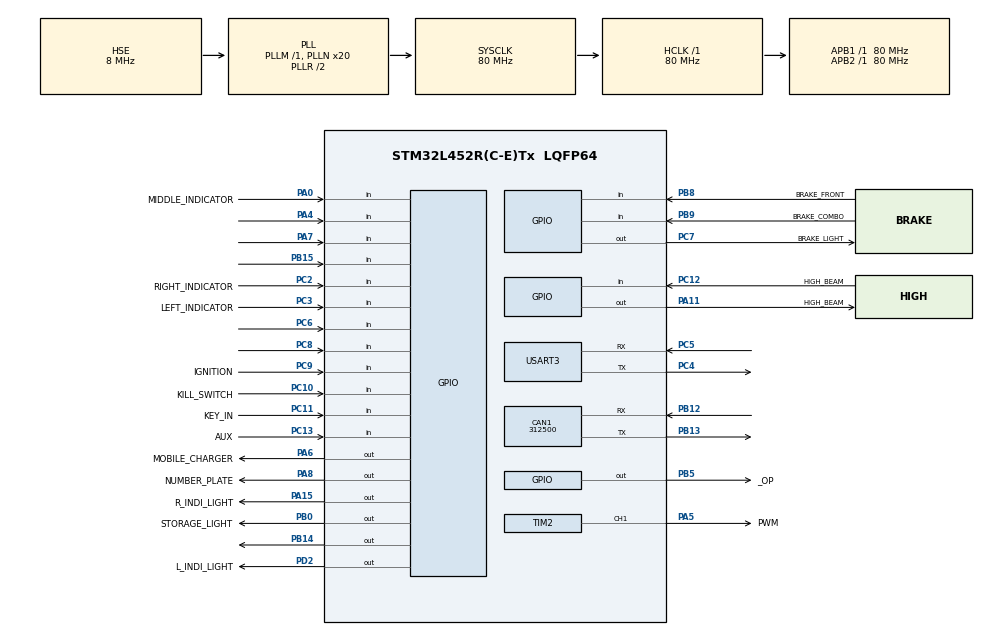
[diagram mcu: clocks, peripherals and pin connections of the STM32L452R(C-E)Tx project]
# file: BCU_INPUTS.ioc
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Mcu.Family=STM32L4
NVIC.CAN1_RX1_IRQn=true\:0\:0\:false\:false\:true\:true\:true
RCC.CortexFreq_Value=80000000
PC10.GPIO_PuPd=GPIO_NOPULL
PH0-OSC_IN\ (PH0).Signal=RCC_OSC_IN
PC12.Signal=GPIO_Input
PC10.Signal=GPIO_Input
PA0.GPIO_Label=MIDDLE_INDICATOR
PA6.GPIO_Label=MOBILE_CHARGER
PB0.GPIO_Label=STORAGE_LIGHT
PA15\ (JTDI).Signal=GPIO_Output
PC5.Mode=Asynchronous
PC13.GPIO_Label=AUX
PB13.Signal=CAN1_TX
PB15.Signal=GPIO_Input
RCC.SYSCLKSource=RCC_SYSCLKSOURCE_PLLCLK
ProjectManager.StackSize=0x400
USART3.VirtualMode-Asynchronous=VM_ASYNC
PC11.GPIO_PuPd=GPIO_NOPULL
PA14\ (JTCK/SWCLK).Signal=SYS_JTCK-SWCLK
NVIC.CAN1_TX_IRQn=true\:0\:0\:false\:false\:true\:true\:true
RCC.HCLKFreq_Value=80000000
RCC.APB2TimFreq_Value=80000000
TIM3.Period=10000
PC7.Signal=GPIO_Output
PC3.Signal=GPIO_Input
NVIC.CAN1_SCE_IRQn=true\:0\:0\:false\:false\:true\:true\:true
RCC.AHBFreq_Value=80000000
PH1-OSC_OUT\ (PH1).Mode=HSE-External-Oscillator
RCC.HSE_VALUE=8000000
PA4.GPIO_PuPd=GPIO_NOPULL
TIM3.Prescaler=4
PC11.GPIO_Label=KEY_IN
PC13.GPIO_PuPd=GPIO_NOPULL
PA8.Signal=GPIO_Output
PA14\ (JTCK/SWCLK).Mode=Serial_Wire
TIM2.Channel-PWM\ Generation1\ CH1=TIM_CHANNEL_1
PA0.Signal=GPIO_Input
Mcu.Package=LQFP64
PB9.Signal=GPIO_Input
TIM2.Prescaler=1600
PA6.Signal=GPIO_Output
PB12.Mode=CAN_Activate
PB15.GPIO_PuPd=GPIO_NOPULL
PA0.GPIO_PuPd=GPIO_NOPULL
PB9.GPIO_PuPd=GPIO_NOPULL
PC6.GPIO_PuPd=GPIO_NOPULL
PB5.GPIO_Label=_OP
RCC.APB1TimFreq_Value=80000000
PC5.Signal=USART3_RX
PB13.Mode=CAN_Activate
PC12.GPIO_PuPd=GPIO_NOPULL
CAN1.CalculateTimeBit=3200.00
PH0-OSC_IN\ (PH0).Mode=HSE-External-Oscillator
PC2.GPIO_Label=RIGHT_INDICATOR
VP_TIM3_VS_ClockSourceINT.Mode=Internal
PC4.Mode=Asynchronous
RCC.HSI48_VALUE=48000000
CAN1.CalculateTimeQuantum=200.0
RCC.MSI_VALUE=4000000
RCC.PLLSourceVirtual=RCC_PLLSOURCE_HSE
SH.S_TIM2_CH1.0=TIM2_CH1,PWM Generation1 CH1
PA13\ (JTMS/SWDIO).Mode=Serial_Wire
PB9.GPIO_Label=BRAKE_COMBO
PC10.GPIO_Label=KILL_SWITCH
PC9.GPIO_Label=IGNITION
TIM3.AutoReloadPreload=TIM_AUTORELOAD_PRELOAD_ENABLE
PC11.Signal=GPIO_Input
PC13.Signal=GPIO_Input
CAN1.CalculateBaudRate=312500
PC8.Signal=GPIO_Input
PB8.GPIO_PuPd=GPIO_NOPULL
PC2.Signal=GPIO_Input
PC4.Signal=USART3_TX
PC6.Signal=GPIO_Input
PA11.GPIO_Label=HIGH_BEAM
PH1-OSC_OUT\ (PH1).Signal=RCC_OSC_OUT
PB8.GPIO_Label=BRAKE_FRONT
PA8.GPIO_Label=NUMBER_PLATE
CAN1.BS2=CAN_BS2_2TQ
CAN1.BS1=CAN_BS1_13TQ
ProjectManager.TargetToolchain=STM32CubeIDE
RCC.USBFreq_Value=32000000
RCC.LSE_VALUE=32768
PA7.GPIO_PuPd=GPIO_NOPULL
PB14.Signal=GPIO_Output
PA5.Signal=S_TIM2_CH1
board=custom
RCC.VCOOutputFreq_Value=160000000
NVIC.TIM3_IRQn=true\:0\:0\:false\:false\:true\:true\:true
RCC.APB2Freq_Value=80000000
VP_TIM2_VS_ClockSourceINT.Mode=Internal
RCC.ADCFreq_Value=32000000
PC9.GPIO_PuPd=GPIO_NOPULL
PC2.GPIO_PuPd=GPIO_NOPULL
TIM2.Period=1000
PA15\ (JTDI).GPIO_Label=R_INDI_LIGHT
Mcu.Name=STM32L452R(C-E)Tx
PC7.GPIO_Label=BRAKE_LIGHT
PC8.GPIO_PuPd=GPIO_NOPULL
PA4.Signal=GPIO_Input
RCC.SYSCLKFreq_VALUE=80000000
PB5.Signal=GPIO_Output
PA5.GPIO_Label=PWM
PC12.GPIO_Label=HIGH_BEAM
PA11.Signal=GPIO_Output
ProjectManager.HeapSize=0x200
RCC.HSI_VALUE=16000000
NVIC.PriorityGroup=NVIC_PRIORITYGROUP_4
RCC.PLLN=20
PB8.Signal=GPIO_Input
TIM2.AutoReloadPreload=TIM_AUTORELOAD_PRELOAD_ENABLE
PC3.GPIO_Label=LEFT_INDICATOR
PC9.Signal=GPIO_Input
PD2.Signal=GPIO_Output
RCC.APB1Freq_Value=80000000
PB0.Signal=GPIO_Output
PB12.Signal=CAN1_RX
PD2.GPIO_Label=L_INDI_LIGHT
NVIC.CAN1_RX0_IRQn=true\:0\:0\:false\:false\:true\:true\:true
PA13\ (JTMS/SWDIO).Signal=SYS_JTMS-SWDIO
PC3.GPIO_PuPd=GPIO_NOPULL
PA7.Signal=GPIO_Input

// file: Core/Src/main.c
/* USER CODE BEGIN Header */
/**
  ******************************************************************************
  * @file           : main.c
  * @brief          : Main program body
  ******************************************************************************
  * @attention
  *
  * <h2><center>&copy; Copyright (c) 2021 STMicroelectronics.
  * All rights reserved.</center></h2>
  *
  * This software component is licensed by ST under BSD 3-Clause license,
  * the "License"; You may not use this file except in compliance with the
  * License. You may obtain a copy of the License at:
  *                        opensource.org/licenses/BSD-3-Clause
  *
  ******************************************************************************
  */
/* USER CODE END Header */
#include "main.h"

CAN_HandleTypeDef hcan1;

TIM_HandleTypeDef htim2;
TIM_HandleTypeDef htim3;

UART_HandleTypeDef huart3;

void SystemClock_Config(void);
static void MX_GPIO_Init(void);
static void MX_CAN1_Init(void);
static void MX_TIM2_Init(void);
static void MX_USART3_UART_Init(void);
static void MX_TIM3_Init(void);

int main(void)
{

  /* MCU Configuration--------------------------------------------------------*/

  /* Reset of all peripherals, Initializes the Flash interface and the Systick. */
  HAL_Init();

  /* Configure the system clock */
  SystemClock_Config();

  /* Initialize all configured peripherals */
  MX_GPIO_Init();
  MX_CAN1_Init();
  MX_TIM2_Init();
  MX_USART3_UART_Init();
  MX_TIM3_Init();
  /* USER CODE BEGIN 2 */
  HAL_TIM_PWM_Start(&htim2, TIM_CHANNEL_1);

  /* USER CODE END 2 */

  /* Infinite loop */
  /* USER CODE BEGIN WHILE */
  while (1)
  {
	  	  htim2.Instance->CCR1 = 50;  // duty cycle is 1ms  0deg
		  HAL_Delay(2000);
		  htim2.Instance->CCR1 = 100;  // duty cycle is 2 ms 180deg
		  HAL_Delay(2000);
		  htim2.Instance->CCR1 = 75;  // duty cycle is 1.5 ms  90deg
		  HAL_Delay(2000);
		  htim2.Instance->CCR1 = 50;  // duty cycle is  1ms  0deg
		  HAL_Delay(2000);

    /* USER CODE END WHILE */

  }
}

void SystemClock_Config(void)
{
  RCC_OscInitTypeDef RCC_OscInitStruct = {0};
  RCC_ClkInitTypeDef RCC_ClkInitStruct = {0};
  RCC_PeriphCLKInitTypeDef PeriphClkInit = {0};

  /** Initializes the RCC Oscillators according to the specified parameters
  * in the RCC_OscInitTypeDef structure.
  */
  RCC_OscInitStruct.OscillatorType = RCC_OSCILLATORTYPE_HSE;
  RCC_OscInitStruct.HSEState = RCC_HSE_ON;
  RCC_OscInitStruct.PLL.PLLState = RCC_PLL_ON;
  RCC_OscInitStruct.PLL.PLLSource = RCC_PLLSOURCE_HSE;
  RCC_OscInitStruct.PLL.PLLM = 1;
  RCC_OscInitStruct.PLL.PLLN = 20;
  RCC_OscInitStruct.PLL.PLLP = RCC_PLLP_DIV7;
  RCC_OscInitStruct.PLL.PLLQ = RCC_PLLQ_DIV2;
  RCC_OscInitStruct.PLL.PLLR = RCC_PLLR_DIV2;
  if (HAL_RCC_OscConfig(&RCC_OscInitStruct) != HAL_OK)
  {
    Error_Handler();
  }
  /** Initializes the CPU, AHB and APB buses clocks
  */
  RCC_ClkInitStruct.ClockType = RCC_CLOCKTYPE_HCLK|RCC_CLOCKTYPE_SYSCLK
                              |RCC_CLOCKTYPE_PCLK1|RCC_CLOCKTYPE_PCLK2;
  RCC_ClkInitStruct.SYSCLKSource = RCC_SYSCLKSOURCE_PLLCLK;
  RCC_ClkInitStruct.AHBCLKDivider = RCC_SYSCLK_DIV1;
  RCC_ClkInitStruct.APB1CLKDivider = RCC_HCLK_DIV1;
  RCC_ClkInitStruct.APB2CLKDivider = RCC_HCLK_DIV1;

  if (HAL_RCC_ClockConfig(&RCC_ClkInitStruct, FLASH_LATENCY_4) != HAL_OK)
  {
    Error_Handler();
  }
  PeriphClkInit.PeriphClockSelection = RCC_PERIPHCLK_USART3;
  PeriphClkInit.Usart3ClockSelection = RCC_USART3CLKSOURCE_PCLK1;
  if (HAL_RCCEx_PeriphCLKConfig(&PeriphClkInit) != HAL_OK)
  {
    Error_Handler();
  }
  /** Configure the main internal regulator output voltage
  */
  if (HAL_PWREx_ControlVoltageScaling(PWR_REGULATOR_VOLTAGE_SCALE1) != HAL_OK)
  {
    Error_Handler();
  }
}

static void MX_CAN1_Init(void)
{

  hcan1.Instance = CAN1;
  hcan1.Init.Prescaler = 16;
  hcan1.Init.Mode = CAN_MODE_NORMAL;
  hcan1.Init.SyncJumpWidth = CAN_SJW_1TQ;
  hcan1.Init.TimeSeg1 = CAN_BS1_13TQ;
  hcan1.Init.TimeSeg2 = CAN_BS2_2TQ;
  hcan1.Init.TimeTriggeredMode = DISABLE;
  hcan1.Init.AutoBusOff = DISABLE;
  hcan1.Init.AutoWakeUp = DISABLE;
  hcan1.Init.AutoRetransmission = DISABLE;
  hcan1.Init.ReceiveFifoLocked = DISABLE;
  hcan1.Init.TransmitFifoPriority = DISABLE;
  if (HAL_CAN_Init(&hcan1) != HAL_OK)
  {
    Error_Handler();
  }

}

static void MX_TIM2_Init(void)
{

  TIM_ClockConfigTypeDef sClockSourceConfig = {0};
  TIM_MasterConfigTypeDef sMasterConfig = {0};
  TIM_OC_InitTypeDef sConfigOC = {0};

  htim2.Instance = TIM2;
  htim2.Init.Prescaler = 1600;
  htim2.Init.CounterMode = TIM_COUNTERMODE_UP;
  htim2.Init.Period = 1000;
  htim2.Init.ClockDivision = TIM_CLOCKDIVISION_DIV1;
  htim2.Init.AutoReloadPreload = TIM_AUTORELOAD_PRELOAD_ENABLE;
  if (HAL_TIM_Base_Init(&htim2) != HAL_OK)
  {
    Error_Handler();
  }
  sClockSourceConfig.ClockSource = TIM_CLOCKSOURCE_INTERNAL;
  if (HAL_TIM_ConfigClockSource(&htim2, &sClockSourceConfig) != HAL_OK)
  {
    Error_Handler();
  }
  if (HAL_TIM_PWM_Init(&htim2) != HAL_OK)
  {
    Error_Handler();
  }
  sMasterConfig.MasterOutputTrigger = TIM_TRGO_RESET;
  sMasterConfig.MasterSlaveMode = TIM_MASTERSLAVEMODE_DISABLE;
  if (HAL_TIMEx_MasterConfigSynchronization(&htim2, &sMasterConfig) != HAL_OK)
  {
    Error_Handler();
  }
  sConfigOC.OCMode = TIM_OCMODE_PWM1;
  sConfigOC.Pulse = 0;
  sConfigOC.OCPolarity = TIM_OCPOLARITY_HIGH;
  sConfigOC.OCFastMode = TIM_OCFAST_DISABLE;
  if (HAL_TIM_PWM_ConfigChannel(&htim2, &sConfigOC, TIM_CHANNEL_1) != HAL_OK)
  {
    Error_Handler();
  }
  HAL_TIM_MspPostInit(&htim2);

}

static void MX_TIM3_Init(void)
{

  TIM_ClockConfigTypeDef sClockSourceConfig = {0};
  TIM_MasterConfigTypeDef sMasterConfig = {0};

  htim3.Instance = TIM3;
  htim3.Init.Prescaler = 4;
  htim3.Init.CounterMode = TIM_COUNTERMODE_UP;
  htim3.Init.Period = 10000;
  htim3.Init.ClockDivision = TIM_CLOCKDIVISION_DIV1;
  htim3.Init.AutoReloadPreload = TIM_AUTORELOAD_PRELOAD_ENABLE;
  if (HAL_TIM_Base_Init(&htim3) != HAL_OK)
  {
    Error_Handler();
  }
  sClockSourceConfig.ClockSource = TIM_CLOCKSOURCE_INTERNAL;
  if (HAL_TIM_ConfigClockSource(&htim3, &sClockSourceConfig) != HAL_OK)
  {
    Error_Handler();
  }
  sMasterConfig.MasterOutputTrigger = TIM_TRGO_RESET;
  sMasterConfig.MasterSlaveMode = TIM_MASTERSLAVEMODE_DISABLE;
  if (HAL_TIMEx_MasterConfigSynchronization(&htim3, &sMasterConfig) != HAL_OK)
  {
    Error_Handler();
  }

}

static void MX_USART3_UART_Init(void)
{

  huart3.Instance = USART3;
  huart3.Init.BaudRate = 115200;
  huart3.Init.WordLength = UART_WORDLENGTH_8B;
  huart3.Init.StopBits = UART_STOPBITS_1;
  huart3.Init.Parity = UART_PARITY_NONE;
  huart3.Init.Mode = UART_MODE_TX_RX;
  huart3.Init.HwFlowCtl = UART_HWCONTROL_NONE;
  huart3.Init.OverSampling = UART_OVERSAMPLING_16;
  huart3.Init.OneBitSampling = UART_ONE_BIT_SAMPLE_DISABLE;
  huart3.AdvancedInit.AdvFeatureInit = UART_ADVFEATURE_NO_INIT;
  if (HAL_UART_Init(&huart3) != HAL_OK)
  {
    Error_Handler();
  }

}

static void MX_GPIO_Init(void)
{
  GPIO_InitTypeDef GPIO_InitStruct = {0};

  /* GPIO Ports Clock Enable */
  __HAL_RCC_GPIOC_CLK_ENABLE();
  __HAL_RCC_GPIOH_CLK_ENABLE();
  __HAL_RCC_GPIOA_CLK_ENABLE();
  __HAL_RCC_GPIOB_CLK_ENABLE();
  __HAL_RCC_GPIOD_CLK_ENABLE();

  /*Configure GPIO pin Output Level */
  HAL_GPIO_WritePin(GPIOA, MOBILE_CHARGER_Pin|NUMBER_PLATE_Pin|HIGH_BEAM_Pin|R_INDI_LIGHT_Pin, GPIO_PIN_RESET);

  /*Configure GPIO pin Output Level */
  HAL_GPIO_WritePin(GPIOB, STORAGE_LIGHT_Pin|GPIO_PIN_14|_OP_Pin, GPIO_PIN_RESET);

  /*Configure GPIO pin Output Level */
  HAL_GPIO_WritePin(BRAKE_LIGHT_GPIO_Port, BRAKE_LIGHT_Pin, GPIO_PIN_RESET);

  /*Configure GPIO pin Output Level */
  HAL_GPIO_WritePin(L_INDI_LIGHT_GPIO_Port, L_INDI_LIGHT_Pin, GPIO_PIN_RESET);

  /*Configure GPIO pins : AUX_Pin RIGHT_INDICATOR_Pin LEFT_INDICATOR_Pin PC6
                           PC8 IGNITION_Pin KILL_SWITCH_Pin KEY_IN_Pin
                           HIGH_BEAMC12_Pin */
  GPIO_InitStruct.Pin = AUX_Pin|RIGHT_INDICATOR_Pin|LEFT_INDICATOR_Pin|GPIO_PIN_6
                          |GPIO_PIN_8|IGNITION_Pin|KILL_SWITCH_Pin|KEY_IN_Pin
                          |HIGH_BEAMC12_Pin;
  GPIO_InitStruct.Mode = GPIO_MODE_INPUT;
  GPIO_InitStruct.Pull = GPIO_NOPULL;
  HAL_GPIO_Init(GPIOC, &GPIO_InitStruct);

  /*Configure GPIO pins : MIDDLE_INDICATOR_Pin PA4 PA7 */
  GPIO_InitStruct.Pin = MIDDLE_INDICATOR_Pin|GPIO_PIN_4|GPIO_PIN_7;
  GPIO_InitStruct.Mode = GPIO_MODE_INPUT;
  GPIO_InitStruct.Pull = GPIO_NOPULL;
  HAL_GPIO_Init(GPIOA, &GPIO_InitStruct);

  /*Configure GPIO pins : MOBILE_CHARGER_Pin NUMBER_PLATE_Pin HIGH_BEAM_Pin R_INDI_LIGHT_Pin */
  GPIO_InitStruct.Pin = MOBILE_CHARGER_Pin|NUMBER_PLATE_Pin|HIGH_BEAM_Pin|R_INDI_LIGHT_Pin;
  GPIO_InitStruct.Mode = GPIO_MODE_OUTPUT_PP;
  GPIO_InitStruct.Pull = GPIO_NOPULL;
  GPIO_InitStruct.Speed = GPIO_SPEED_FREQ_LOW;
  HAL_GPIO_Init(GPIOA, &GPIO_InitStruct);

  /*Configure GPIO pins : STORAGE_LIGHT_Pin PB14 _OP_Pin */
  GPIO_InitStruct.Pin = STORAGE_LIGHT_Pin|GPIO_PIN_14|_OP_Pin;
  GPIO_InitStruct.Mode = GPIO_MODE_OUTPUT_PP;
  GPIO_InitStruct.Pull = GPIO_NOPULL;
  GPIO_InitStruct.Speed = GPIO_SPEED_FREQ_LOW;
  HAL_GPIO_Init(GPIOB, &GPIO_InitStruct);

  /*Configure GPIO pins : PB15 BRAKE_FRONT_Pin BRAKE_COMBO_Pin */
  GPIO_InitStruct.Pin = GPIO_PIN_15|BRAKE_FRONT_Pin|BRAKE_COMBO_Pin;
  GPIO_InitStruct.Mode = GPIO_MODE_INPUT;
  GPIO_InitStruct.Pull = GPIO_NOPULL;
  HAL_GPIO_Init(GPIOB, &GPIO_InitStruct);

  /*Configure GPIO pin : BRAKE_LIGHT_Pin */
  GPIO_InitStruct.Pin = BRAKE_LIGHT_Pin;
  GPIO_InitStruct.Mode = GPIO_MODE_OUTPUT_PP;
  GPIO_InitStruct.Pull = GPIO_NOPULL;
  GPIO_InitStruct.Speed = GPIO_SPEED_FREQ_LOW;
  HAL_GPIO_Init(BRAKE_LIGHT_GPIO_Port, &GPIO_InitStruct);

  /*Configure GPIO pin : L_INDI_LIGHT_Pin */
  GPIO_InitStruct.Pin = L_INDI_LIGHT_Pin;
  GPIO_InitStruct.Mode = GPIO_MODE_OUTPUT_PP;
  GPIO_InitStruct.Pull = GPIO_NOPULL;
  GPIO_InitStruct.Speed = GPIO_SPEED_FREQ_LOW;
  HAL_GPIO_Init(L_INDI_LIGHT_GPIO_Port, &GPIO_InitStruct);

}

void Error_Handler(void)
{
  __disable_irq();
  while (1)
  {
  }
}

/************************ (C) COPYRIGHT STMicroelectronics *****END OF FILE****/
